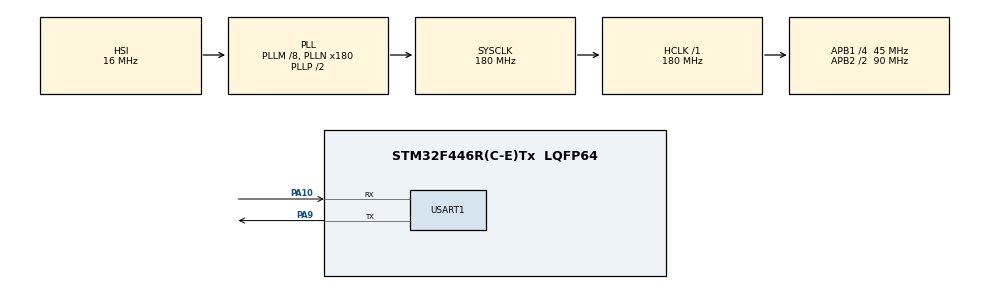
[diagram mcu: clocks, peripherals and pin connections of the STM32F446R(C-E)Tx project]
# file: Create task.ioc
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FREERTOS.Tasks01=defaultTask,0,128,StartDefaultTask,Default,NULL,Dynamic,NULL,NULL
Mcu.Family=STM32F4
Mcu.Name=STM32F446R(C-E)Tx
Mcu.Package=LQFP64
NVIC.PriorityGroup=NVIC_PRIORITYGROUP_4
NVIC.TIM1_UP_TIM10_IRQn=true\:0\:0\:false\:false\:true\:false\:true
NVIC.TimeBase=TIM1_UP_TIM10_IRQn
NVIC.TimeBaseIP=TIM1
PA10.Mode=Asynchronous
PA10.Signal=USART1_RX
PA9.Mode=Asynchronous
PA9.Signal=USART1_TX
PH0-OSC_IN.Mode=HSE-External-Clock-Source
PH0-OSC_IN.Signal=RCC_OSC_IN
PH1-OSC_OUT.Mode=HSE-External-Clock-Source
PH1-OSC_OUT.Signal=RCC_OSC_OUT
ProjectManager.HeapSize=0x200
ProjectManager.StackSize=0x400
ProjectManager.TargetToolchain=MDK-ARM V5.27
RCC.AHBFreq_Value=180000000
RCC.APB1CLKDivider=RCC_HCLK_DIV4
RCC.APB1Freq_Value=45000000
RCC.APB1TimFreq_Value=90000000
RCC.APB2CLKDivider=RCC_HCLK_DIV2
RCC.APB2Freq_Value=90000000
RCC.APB2TimFreq_Value=180000000
RCC.CortexFreq_Value=180000000
RCC.HCLKFreq_Value=180000000
RCC.PLLM=8
RCC.PLLN=180
RCC.SYSCLKFreq_VALUE=180000000
RCC.SYSCLKSource=RCC_SYSCLKSOURCE_PLLCLK
RCC.USBFreq_Value=180000000
RCC.VCOOutputFreq_Value=360000000
USART1.VirtualMode=VM_ASYNC
VP_FREERTOS_VS_CMSIS_V1.Mode=CMSIS_V1
VP_SYS_VS_tim1.Mode=TIM1
board=custom

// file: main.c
/* USER CODE BEGIN Header */
/**
  ******************************************************************************
  * @file           : main.c
  * @brief          : Main program body
  ******************************************************************************
  * @attention
  *
  * <h2><center>&copy; Copyright (c) 2023 STMicroelectronics.
  * All rights reserved.</center></h2>
  *
  * This software component is licensed by ST under Ultimate Liberty license
  * SLA0044, the "License"; You may not use this file except in compliance with
  * the License. You may obtain a copy of the License at:
  *                             www.st.com/SLA0044
  *
  ******************************************************************************
  */
/* USER CODE END Header */
#include "main.h"
#include "cmsis_os.h"

UART_HandleTypeDef huart1;

osThreadId greenLEDHandle;
osThreadId blueLEDHandle;
osThreadId redLEDHandle;

void SystemClock_Config(void);
static void MX_GPIO_Init(void);
static void MX_USART1_UART_Init(void);
void greenController(void const * argument);
void blueController(void const * argument);
void redController(void const * argument);

/* USER CODE BEGIN 0 */
const TickType_t _50ms = pdMS_TO_TICKS(50); //50 ms equivalaent ticks store in a variable
/* USER CODE END 0 */

int main(void)
{

  /* MCU Configuration--------------------------------------------------------*/

  /* Reset of all peripherals, Initializes the Flash interface and the Systick. */
  HAL_Init();

  /* Configure the system clock */
  SystemClock_Config();

  /* Initialize all configured peripherals */
  MX_GPIO_Init();
  MX_USART1_UART_Init();

  /* Create the thread(s) */
  /* definition and creation of greenLED */
  osThreadDef(greenLED, greenController, osPriorityNormal, 0, 128);
  greenLEDHandle = osThreadCreate(osThread(greenLED), NULL);

  /* definition and creation of blueLED */
  osThreadDef(blueLED, blueController, osPriorityIdle, 0, 128);
  blueLEDHandle = osThreadCreate(osThread(blueLED), NULL);

  /* definition and creation of redLED */
  osThreadDef(redLED, redController, osPriorityIdle, 0, 128);
  redLEDHandle = osThreadCreate(osThread(redLED), NULL);

  /* Start scheduler */
  osKernelStart();

  /* We should never get here as control is now taken by the scheduler */
  /* Infinite loop */
  while (1)
  {

  }
}

void SystemClock_Config(void)
{
  RCC_OscInitTypeDef RCC_OscInitStruct = {0};
  RCC_ClkInitTypeDef RCC_ClkInitStruct = {0};

  /** Configure the main internal regulator output voltage
  */
  __HAL_RCC_PWR_CLK_ENABLE();
  __HAL_PWR_VOLTAGESCALING_CONFIG(PWR_REGULATOR_VOLTAGE_SCALE1);
  /** Initializes the RCC Oscillators according to the specified parameters
  * in the RCC_OscInitTypeDef structure.
  */
  RCC_OscInitStruct.OscillatorType = RCC_OSCILLATORTYPE_HSI;
  RCC_OscInitStruct.HSIState = RCC_HSI_ON;
  RCC_OscInitStruct.HSICalibrationValue = RCC_HSICALIBRATION_DEFAULT;
  RCC_OscInitStruct.PLL.PLLState = RCC_PLL_ON;
  RCC_OscInitStruct.PLL.PLLSource = RCC_PLLSOURCE_HSI;
  RCC_OscInitStruct.PLL.PLLM = 8;
  RCC_OscInitStruct.PLL.PLLN = 180;
  RCC_OscInitStruct.PLL.PLLP = RCC_PLLP_DIV2;
  RCC_OscInitStruct.PLL.PLLQ = 2;
  RCC_OscInitStruct.PLL.PLLR = 2;
  if (HAL_RCC_OscConfig(&RCC_OscInitStruct) != HAL_OK)
  {
    Error_Handler();
  }
  /** Activate the Over-Drive mode
  */
  if (HAL_PWREx_EnableOverDrive() != HAL_OK)
  {
    Error_Handler();
  }
  /** Initializes the CPU, AHB and APB buses clocks
  */
  RCC_ClkInitStruct.ClockType = RCC_CLOCKTYPE_HCLK|RCC_CLOCKTYPE_SYSCLK
                              |RCC_CLOCKTYPE_PCLK1|RCC_CLOCKTYPE_PCLK2;
  RCC_ClkInitStruct.SYSCLKSource = RCC_SYSCLKSOURCE_PLLCLK;
  RCC_ClkInitStruct.AHBCLKDivider = RCC_SYSCLK_DIV1;
  RCC_ClkInitStruct.APB1CLKDivider = RCC_HCLK_DIV4;
  RCC_ClkInitStruct.APB2CLKDivider = RCC_HCLK_DIV2;

  if (HAL_RCC_ClockConfig(&RCC_ClkInitStruct, FLASH_LATENCY_5) != HAL_OK)
  {
    Error_Handler();
  }
}

static void MX_USART1_UART_Init(void)
{

  huart1.Instance = USART1;
  huart1.Init.BaudRate = 115200;
  huart1.Init.WordLength = UART_WORDLENGTH_8B;
  huart1.Init.StopBits = UART_STOPBITS_1;
  huart1.Init.Parity = UART_PARITY_NONE;
  huart1.Init.Mode = UART_MODE_TX_RX;
  huart1.Init.HwFlowCtl = UART_HWCONTROL_NONE;
  huart1.Init.OverSampling = UART_OVERSAMPLING_16;
  if (HAL_UART_Init(&huart1) != HAL_OK)
  {
    Error_Handler();
  }

}

static void MX_GPIO_Init(void)
{

  /* GPIO Ports Clock Enable */
  __HAL_RCC_GPIOH_CLK_ENABLE();
  __HAL_RCC_GPIOA_CLK_ENABLE();

}

uint32_t suspend;
void greenController(void const * argument)
{
  /* USER CODE BEGIN 5 */
  /* Infinite loop */
  for(;;)
  {
		/*for(int i=0; i<7000000; i++)
		{
			osThreadSetPriority(greenLEDHandle, 2); //change the priority in run time
		}*/
		//
    osDelay(1);

		/* if(suspend <= 50)
		{
			osThreadSuspend(greenLEDHandle);  //sudden a task off
		}*/

  }
  /* USER CODE END 5 */
}

void blueController(void const * argument)
{
  /* USER CODE BEGIN blueController */
	TickType_t xLastWakeTime;
	const TickType_t xPeriod = pdMS_TO_TICKS(500);

	xLastWakeTime =  xTaskGetTickCount();  //every tick will count the processor
  /* Infinite loop */
  for(;;) //or while(1)
  {
		vTaskDelayUntil(&xLastWakeTime, xPeriod); //this is for very precise delay where every freq will count
    osDelay(1);
  }
  /* USER CODE END blueController */
}

void redController(void const * argument)
{
  /* USER CODE BEGIN redController */
  /* Infinite loop */
  for(;;)
  {
		vTaskDelay(50);
    osDelay(1);
  }
  /* USER CODE END redController */
}

 /**
  * @brief  Period elapsed callback in non blocking mode
  * @note   This function is called  when TIM1 interrupt took place, inside
  * HAL_TIM_IRQHandler(). It makes a direct call to HAL_IncTick() to increment
  * a global variable "uwTick" used as application time base.
  * @param  htim : TIM handle
  * @retval None
  */
void HAL_TIM_PeriodElapsedCallback(TIM_HandleTypeDef *htim)
{
  if (htim->Instance == TIM1) {
    HAL_IncTick();
  }
}

void Error_Handler(void)
{
  __disable_irq();
  while (1)
  {
  }
}

/************************ (C) COPYRIGHT STMicroelectronics *****END OF FILE****/
